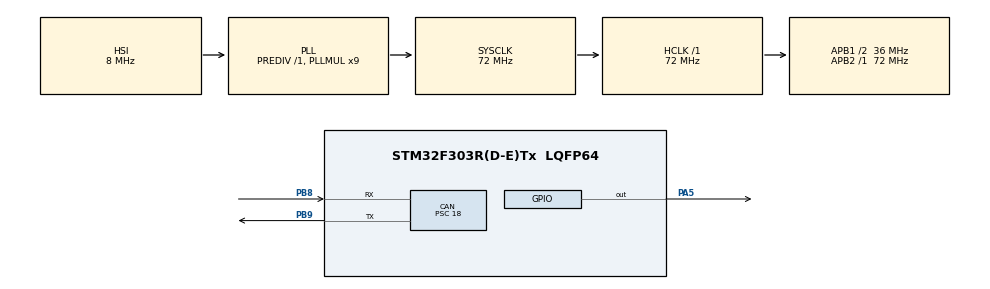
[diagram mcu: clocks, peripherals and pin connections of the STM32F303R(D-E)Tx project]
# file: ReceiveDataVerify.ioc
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CAN.BS1=CAN_BS1_4TQ
CAN.BS2=CAN_BS2_3TQ
CAN.CalculateTimeBit=4000
CAN.CalculateTimeQuantum=500.0
CAN.Prescaler=18
CAN.SJW=CAN_SJW_4TQ
Mcu.Family=STM32F3
Mcu.Name=STM32F303R(D-E)Tx
Mcu.Package=LQFP64
NVIC.CAN_RX1_IRQn=true\:0\:0\:false\:false\:true\:true
NVIC.CAN_SCE_IRQn=true\:0\:0\:false\:false\:true\:true
NVIC.PriorityGroup=NVIC_PRIORITYGROUP_4
NVIC.TIM1_UP_TIM16_IRQn=true\:0\:0\:false\:false\:true\:true
NVIC.USB_HP_CAN_TX_IRQn=true\:0\:0\:false\:false\:true\:true
NVIC.USB_LP_CAN_RX0_IRQn=true\:0\:0\:false\:false\:true\:true
PA5.Signal=GPIO_Output
PB8.Mode=Master
PB8.Signal=CAN_RX
PB9.Mode=Master
PB9.Signal=CAN_TX
PF0-OSC_IN.Mode=HSE-External-Oscillator
PF0-OSC_IN.Signal=RCC_OSC_IN
PF1-OSC_OUT.Mode=HSE-External-Oscillator
PF1-OSC_OUT.Signal=RCC_OSC_OUT
ProjectManager.HeapSize=0x200
ProjectManager.StackSize=0x400
ProjectManager.TargetToolchain=TrueSTUDIO
RCC.AHBFreq_Value=72000000
RCC.APB1CLKDivider=RCC_HCLK_DIV2
RCC.APB1Freq_Value=36000000
RCC.APB1TimFreq_Value=72000000
RCC.APB2Freq_Value=72000000
RCC.APB2TimFreq_Value=72000000
RCC.CortexFreq_Value=72000000
RCC.HCLKFreq_Value=72000000
RCC.HSE_VALUE=8000000
RCC.HSI_VALUE=8000000
RCC.LSE_VALUE=32768
RCC.PLLMUL=RCC_PLL_MUL9
RCC.SYSCLKFreq_VALUE=72000000
RCC.SYSCLKSourceVirtual=RCC_SYSCLKSOURCE_PLLCLK
RCC.USBFreq_Value=72000000
TIM16.Period=13399
TIM16.Prescaler=9999
VP_TIM16_VS_ClockSourceINT.Mode=Enable_Timer
board=ReceiveDataVerify

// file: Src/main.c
/**
  ******************************************************************************
  * File Name          : main.c
  * Description        : Main program body
  ******************************************************************************
  ** This notice applies to any and all portions of this file
  * that are not between comment pairs USER CODE BEGIN and
  * USER CODE END. Other portions of this file, whether
  * inserted by the user or by software development tools
  * are owned by their respective copyright owners.
  *
  * COPYRIGHT(c) 2018 STMicroelectronics
  *
  * Redistribution and use in source and binary forms, with or without modification,
  * are permitted provided that the following conditions are met:
  *   1. Redistributions of source code must retain the above copyright notice,
  *      this list of conditions and the following disclaimer.
  *   2. Redistributions in binary form must reproduce the above copyright notice,
  *      this list of conditions and the following disclaimer in the documentation
  *      and/or other materials provided with the distribution.
  *   3. Neither the name of STMicroelectronics nor the names of its contributors
  *      may be used to endorse or promote products derived from this software
  *      without specific prior written permission.
  *
  * THIS SOFTWARE IS PROVIDED BY THE COPYRIGHT HOLDERS AND CONTRIBUTORS "AS IS"
  * AND ANY EXPRESS OR IMPLIED WARRANTIES, INCLUDING, BUT NOT LIMITED TO, THE
  * IMPLIED WARRANTIES OF MERCHANTABILITY AND FITNESS FOR A PARTICULAR PURPOSE ARE
  * DISCLAIMED. IN NO EVENT SHALL THE COPYRIGHT HOLDER OR CONTRIBUTORS BE LIABLE
  * FOR ANY DIRECT, INDIRECT, INCIDENTAL, SPECIAL, EXEMPLARY, OR CONSEQUENTIAL
  * DAMAGES (INCLUDING, BUT NOT LIMITED TO, PROCUREMENT OF SUBSTITUTE GOODS OR
  * SERVICES; LOSS OF USE, DATA, OR PROFITS; OR BUSINESS INTERRUPTION) HOWEVER
  * CAUSED AND ON ANY THEORY OF LIABILITY, WHETHER IN CONTRACT, STRICT LIABILITY,
  * OR TORT (INCLUDING NEGLIGENCE OR OTHERWISE) ARISING IN ANY WAY OUT OF THE USE
  * OF THIS SOFTWARE, EVEN IF ADVISED OF THE POSSIBILITY OF SUCH DAMAGE.
  *
  ******************************************************************************
  */

#include "main.h"
#include "stm32f3xx_hal.h"

/* USER CODE BEGIN Includes */
//#include "stm32f3xx_ll_system.h" //biblioteka do remapowania usb
/* USER CODE END Includes */

CAN_HandleTypeDef hcan;

TIM_HandleTypeDef htim16;

/* USER CODE BEGIN PV */
/* Private variables ---------------------------------------------------------*/
CanRxMsgTypeDef Receive;
CanRxMsgTypeDef Receive2; //do drugiej kolejki
CAN_FilterConfTypeDef Filtr;
/* USER CODE END PV */

void SystemClock_Config(void);
static void MX_GPIO_Init(void);
static void MX_CAN_Init(void);
static void MX_TIM16_Init(void);

/* USER CODE BEGIN PFP */
/* Private function prototypes -----------------------------------------------*/

void HAL_CAN_RxCpltCallback (CAN_HandleTypeDef *hcan)
{
	// if(Receive.Data[0]==0x0013 && Receive.Data[1]==0x0005 && Receive.Data[2]==0x0041)
	if(Receive.Data[0]==0x0013)
	{
		HAL_GPIO_WritePin(GPIOA,GPIO_PIN_5, GPIO_PIN_SET); //œwiecimy jeœli odbierzemy ramke
		TIM16->CNT=0;
		HAL_TIM_Base_Start_IT(&htim16);
		HAL_CAN_Receive_IT(hcan,0);
	}
}

void HAL_TIM_PeriodElapsedCallback(TIM_HandleTypeDef *htim)
{
	if(htim->Instance == TIM16)
	{
		HAL_GPIO_WritePin(GPIOA,GPIO_PIN_5, GPIO_PIN_RESET);
		HAL_TIM_Base_Stop_IT(&htim16);
	}
}
/* USER CODE END PFP */

int main(void)
{

  /* MCU Configuration----------------------------------------------------------*/

  /* Reset of all peripherals, Initializes the Flash interface and the Systick. */
  HAL_Init();

  /* Configure the system clock */
  SystemClock_Config();

  /* USER CODE BEGIN SysInit */
 // LL_SYSCFG_EnableRemapIT_USB(); //podobno trzeba to makro ale chyba dzia³a bez :)
  /* USER CODE END SysInit */

  /* Initialize all configured peripherals */
  MX_GPIO_Init();
  MX_CAN_Init();
  MX_TIM16_Init();

  /* USER CODE BEGIN 2 */
  //HAL_GPIO_WritePin(GPIOA,GPIO_PIN_5,GPIO_PIN_RESET);

  // konfiguracja przerwañ w CAN-ie
  __HAL_CAN_ENABLE_IT(&hcan, CAN_IT_FMP0);
  __HAL_CAN_ENABLE_IT(&hcan, CAN_IT_FMP1);

  Filtr.FilterNumber=1;
  Filtr.FilterMode=CAN_FILTERMODE_IDMASK;	//ustawiamy filtrowanie przez maskê, a nie przez listê
  Filtr.FilterMaskIdHigh=0xFFFF;	// obie maski na 1
  Filtr.FilterMaskIdLow=0xFFFF;
  Filtr.FilterIdHigh=0x0020 << 5; //ustawiamy takie highID jakie ID ma p³ytka wysy³aj¹ca oraz przesuwamy bitowo o 5, bo ID ma 11 bitów
  Filtr.FilterIdLow=0x0000; //troche nie wiemy czemu ale zmiana low nic nie zmienia w dzia³aniu naszego kodu - bo tutaj w tym trybie filtrów podajecie drugi identyfikator, który filtr przepusci
  Filtr.FilterActivation=ENABLE; //aktywacja filtra
  HAL_CAN_ConfigFilter(&hcan,&Filtr); //odpalenie filtra
  hcan.pRxMsg=&Receive;
  hcan.pRx1Msg=&Receive2;
  HAL_CAN_Receive_IT(&hcan,0); //pierwsze przerwanie CAN

  HAL_TIM_Base_Start_IT(&htim16); //tutaj wykonujemy start, stop i wyzerowanie timera, ¿eby wyeliminowac b³¹d, w którym
  HAL_TIM_Base_Stop_IT(&htim16);  // pierwsze przerwanie nie dzia³a³o poprawnie
  TIM16->CNT=0;

  /* USER CODE END 2 */

  /* Infinite loop */
  while (1)
  {

  }

}

/** System Clock Configuration
*/
void SystemClock_Config(void)
{

  RCC_OscInitTypeDef RCC_OscInitStruct;
  RCC_ClkInitTypeDef RCC_ClkInitStruct;
  RCC_PeriphCLKInitTypeDef PeriphClkInit;

    /**Initializes the CPU, AHB and APB busses clocks
    */
  RCC_OscInitStruct.OscillatorType = RCC_OSCILLATORTYPE_HSI;
  RCC_OscInitStruct.HSIState = RCC_HSI_ON;
  RCC_OscInitStruct.HSICalibrationValue = 16;
  RCC_OscInitStruct.PLL.PLLState = RCC_PLL_ON;
  RCC_OscInitStruct.PLL.PLLSource = RCC_PLLSOURCE_HSI;
  RCC_OscInitStruct.PLL.PLLMUL = RCC_PLL_MUL9;
  RCC_OscInitStruct.PLL.PREDIV = RCC_PREDIV_DIV1;
  if (HAL_RCC_OscConfig(&RCC_OscInitStruct) != HAL_OK)
  {
    _Error_Handler(__FILE__, __LINE__);
  }

    /**Initializes the CPU, AHB and APB busses clocks
    */
  RCC_ClkInitStruct.ClockType = RCC_CLOCKTYPE_HCLK|RCC_CLOCKTYPE_SYSCLK
                              |RCC_CLOCKTYPE_PCLK1|RCC_CLOCKTYPE_PCLK2;
  RCC_ClkInitStruct.SYSCLKSource = RCC_SYSCLKSOURCE_PLLCLK;
  RCC_ClkInitStruct.AHBCLKDivider = RCC_SYSCLK_DIV1;
  RCC_ClkInitStruct.APB1CLKDivider = RCC_HCLK_DIV2;
  RCC_ClkInitStruct.APB2CLKDivider = RCC_HCLK_DIV1;

  if (HAL_RCC_ClockConfig(&RCC_ClkInitStruct, FLASH_LATENCY_2) != HAL_OK)
  {
    _Error_Handler(__FILE__, __LINE__);
  }

  PeriphClkInit.PeriphClockSelection = RCC_PERIPHCLK_TIM16;
  PeriphClkInit.Tim16ClockSelection = RCC_TIM16CLK_HCLK;
  if (HAL_RCCEx_PeriphCLKConfig(&PeriphClkInit) != HAL_OK)
  {
    _Error_Handler(__FILE__, __LINE__);
  }

    /**Configure the Systick interrupt time
    */
  HAL_SYSTICK_Config(HAL_RCC_GetHCLKFreq()/1000);

    /**Configure the Systick
    */
  HAL_SYSTICK_CLKSourceConfig(SYSTICK_CLKSOURCE_HCLK);

  /* SysTick_IRQn interrupt configuration */
  HAL_NVIC_SetPriority(SysTick_IRQn, 0, 0);
}

/* CAN init function */
static void MX_CAN_Init(void)
{

  hcan.Instance = CAN;
  hcan.Init.Prescaler = 18;
  hcan.Init.Mode = CAN_MODE_NORMAL;
  hcan.Init.SJW = CAN_SJW_4TQ;
  hcan.Init.BS1 = CAN_BS1_4TQ;
  hcan.Init.BS2 = CAN_BS2_3TQ;
  hcan.Init.TTCM = DISABLE;
  hcan.Init.ABOM = DISABLE;
  hcan.Init.AWUM = DISABLE;
  hcan.Init.NART = DISABLE;
  hcan.Init.RFLM = DISABLE;
  hcan.Init.TXFP = DISABLE;
  if (HAL_CAN_Init(&hcan) != HAL_OK)
  {
    _Error_Handler(__FILE__, __LINE__);
  }

}

/* TIM16 init function */
static void MX_TIM16_Init(void)
{

  htim16.Instance = TIM16;
  htim16.Init.Prescaler = 9999;
  htim16.Init.CounterMode = TIM_COUNTERMODE_UP;
  htim16.Init.Period = 13399;
  htim16.Init.ClockDivision = TIM_CLOCKDIVISION_DIV1;
  htim16.Init.RepetitionCounter = 0;
  htim16.Init.AutoReloadPreload = TIM_AUTORELOAD_PRELOAD_DISABLE;
  if (HAL_TIM_Base_Init(&htim16) != HAL_OK)
  {
    _Error_Handler(__FILE__, __LINE__);
  }

}

/** Configure pins as
        * Analog
        * Input
        * Output
        * EVENT_OUT
        * EXTI
*/
static void MX_GPIO_Init(void)
{

  GPIO_InitTypeDef GPIO_InitStruct;

  /* GPIO Ports Clock Enable */
  __HAL_RCC_GPIOF_CLK_ENABLE();
  __HAL_RCC_GPIOA_CLK_ENABLE();
  __HAL_RCC_GPIOB_CLK_ENABLE();

  /*Configure GPIO pin Output Level */
  HAL_GPIO_WritePin(GPIOA, GPIO_PIN_5, GPIO_PIN_RESET);

  /*Configure GPIO pin : PA5 */
  GPIO_InitStruct.Pin = GPIO_PIN_5;
  GPIO_InitStruct.Mode = GPIO_MODE_OUTPUT_PP;
  GPIO_InitStruct.Pull = GPIO_NOPULL;
  GPIO_InitStruct.Speed = GPIO_SPEED_FREQ_LOW;
  HAL_GPIO_Init(GPIOA, &GPIO_InitStruct);

}

void _Error_Handler(char * file, int line)
{
  while(1)
  {
  }
}

/************************ (C) COPYRIGHT STMicroelectronics *****END OF FILE****/
